# GD32W515 register map
File version: 1.0
CPU: CM33 r0p4, little endian, MPU, FPU, 4 interrupt priority bits
Registers are 32-bit, read-write, reset 0x0 unless marked. A register's access mark holds for its fields unless they carry their own. Offsets are from the block's base; [hi:lo] are bit positions; {n}, {i} and the like mark numbered series; 'fields as' and 'values as' point back to an identical list.

## PKCAU — Public Key Cryptographic Acceleration Unit
Base 0x4C061000
Same registers: SEC_PKCAU 0x5C061000
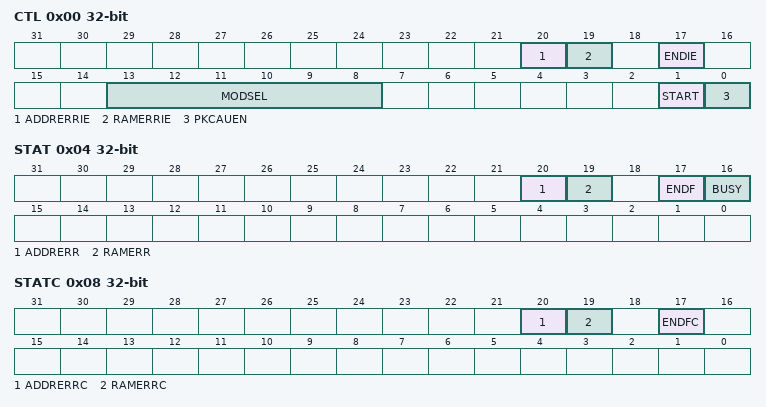
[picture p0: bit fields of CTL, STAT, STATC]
0x00 CTL — Control register
  [20] ADDRERRIE — Address error interrupt enable
  [19] RAMERRIE — RAM error interrupt enable
  [17] ENDIE — End of operation interrupt enable
  [13:8] MODSEL — PKCAU operation mode selection
  [1] START — PKCAU starts operation
  [0] PKCAUEN — PKCAU enable
0x04 STAT ro — Status register
  [20] ADDRERR — Address error
  [19] RAMERR — PKCAU RAM error
  [17] ENDF — End of PKCAU operation
  [16] BUSY — Busy flag
0x08 STATC wo — Status clear register
  [20] ADDRERRC — Address error flag clear
  [19] RAMERRC — PKCAU RAM error flag clear
  [17] ENDFC — End of PKCAU operation flag clear

## PMU — Power management unit
Base 0x40007000
Same registers: SEC_PMU 0x50007000
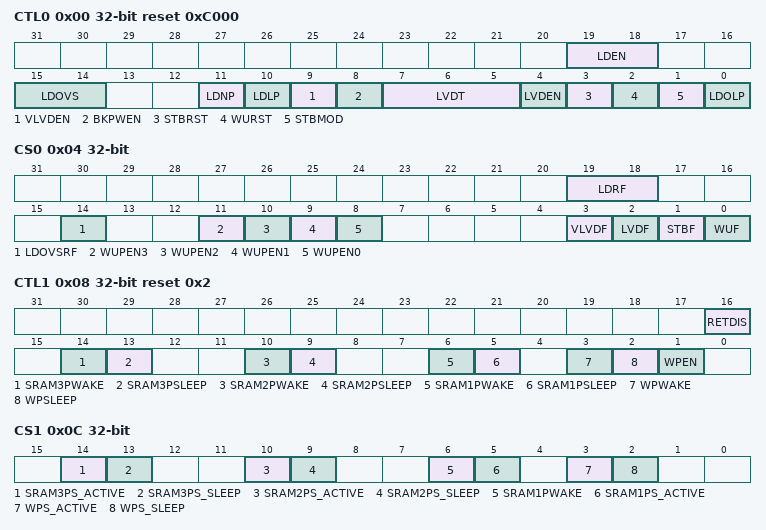
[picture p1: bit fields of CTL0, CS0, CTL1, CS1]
0x00 CTL0 reset 0xC000 — power control register 0
  [19:18] LDEN — Low-driver mode enable in Deep-sleep mode
  [15:14] LDOVS — LDO output voltage select
  [11] LDNP — Low-driver mode when use normal power LDO
  [10] LDLP — Low-driver mode when use low power LDO
  [9] VLVDEN — VDDA low voltage detect enable
  [8] BKPWEN — Backup Domain Write Enable
  [7:5] LVDT — Low Voltage Detector Threshold
  [4] LVDEN — Low Voltage Detector Enable
  [3] STBRST — Standby Flag Reset
  [2] WURST — Wakeup Flag Reset
  [1] STBMOD — Standby Mode
  [0] LDOLP — LDO Low Power Mode
0x04 CS0 access per field — power control/status register 0
  [19:18] LDRF rw — Low-driver mode ready flag
  [14] LDOVSRF ro — LDO voltage select ready flag
  [11] WUPEN3 rw — WKUP Pin3(PA12) Enable
  [10] WUPEN2 rw — WKUP Pin2(PB2) Enable
  [9] WUPEN1 rw — WKUP Pin1(PA15) Enable
  [8] WUPEN0 rw — WKUP Pin0(PA2) Enable
  [3] VLVDF ro — VDDA Low Voltage Detector Status Flag
  [2] LVDF ro — Low Voltage Detector Status Flag
  [1] STBF ro — Standby flag
  [0] WUF ro — Wakeup flag
0x08 CTL1 reset 0x2 — Control register 1
  [16] RETDIS — No retention register when WIFI por-off
  [14] SRAM3PWAKE — SRAM3 wakeup by software
  [13] SRAM3PSLEEP — SRAM3 go to sleep by software
  [10] SRAM2PWAKE — SRAM2 wakeup by software
  [9] SRAM2PSLEEP — SRAM2 go to sleep by software
  [6] SRAM1PWAKE — SRAM1 wakeup by software
  [5] SRAM1PSLEEP — SRAM1 go to sleep by software
  [3] WPWAKE — WIFI wakeup
  [2] WPSLEEP — WIFI go to sleep by software only when WPEN bit is 1
  [1] WPEN — WIFI power enable
0x0C CS1 ro — Control and status register 1
  [14] SRAM3PS_ACTIVE — SRAM3 is in active state
  [13] SRAM3PS_SLEEP — SRAM3 is in sleep state
  [10] SRAM2PS_ACTIVE — SRAM2 is in active state
  [9] SRAM2PS_SLEEP — SRAM2 is in sleep state
  [6] SRAM1PWAKE — SRAM1 wakeup by software
  [5] SRAM1PS_ACTIVE — SRAM1 is in active state
  [3] WPS_ACTIVE — WIFI is in active state
  [2] WPS_SLEEP — WIFI is in sleep state
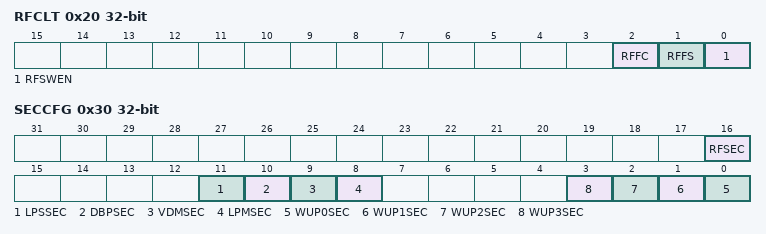
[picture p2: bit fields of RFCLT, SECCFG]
0x20 RFCLT — RF Control register
  [2] RFFC
  [1] RFFS
  [0] RFSWEN — RF sequence configured
0x30 SECCFG — Secure configuration register
  [16] RFSEC — RF security
  [11] LPSSEC — WIFI_sleep and SRAM_sleep mode security
  [10] DBPSEC — Backup Domain write access security
  [9] VDMSEC — Voltage detection and monitoring security
  [8] LPMSEC — Low-power mode security
  [n] WUP{n}SEC (n=0..3) — WKUP pin {n} security
0x34 PRICFG — Privilege configuration register
  [0] PRIV — PMU privileged access

## QSPI — Quad-SPI interface
Base 0x40025800
Same registers: SEC_QSPI 0x50025800
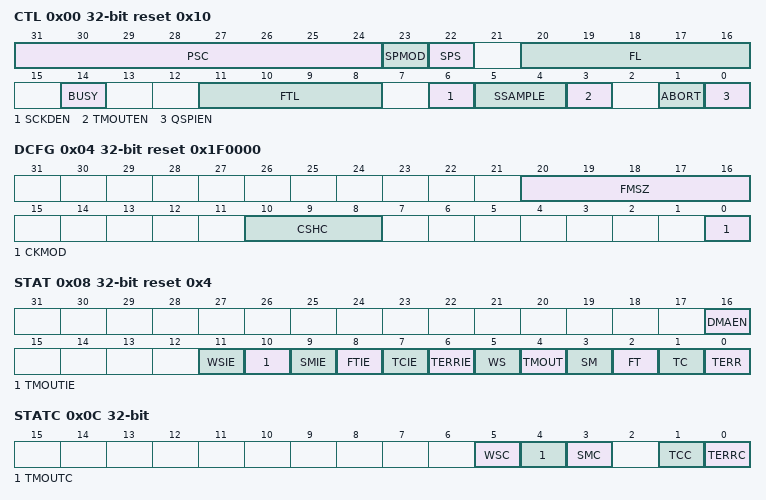
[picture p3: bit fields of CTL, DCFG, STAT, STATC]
0x00 CTL access per field reset 0x10 — Control register
  [31:24] PSC rw — This field defines the scaler factor for generating SCK based on the AHB clock
  [23] SPMOD rw — Status Polling match mode
  [22] SPS rw — Status polling mode stop
  [20:16] FL ro — FIFO level
  [14] BUSY ro
  [11:8] FTL rw — FIFO threshold level
  [6] SCKDEN rw — SCK delay enable when read data from flash, it is only useful when sample shift is 1
  [5:4] SSAMPLE rw — Sample shift
  [3] TMOUTEN rw — Timeout counter enable
  [1] ABORT wo — Abort request
  [0] QSPIEN rw — Enable
0x04 DCFG reset 0x1F0000 — Device configuration register
  [20:16] FMSZ — Flash memory size
  [10:8] CSHC — Chip select high cycle
  [0] CKMOD — This bit indicates the SCK level when QSPI is free.
0x08 STAT access per field reset 0x4 — Status register
  [16] DMAEN rw — DMA enable
  [11] WSIE rw — Wrong start sequence interrupt enable
  [10] TMOUTIE rw — Timeout interrupt enable
  [9] SMIE rw — Status match interrupt enable
  [8] FTIE rw — FIFO threshold interrupt enable
  [7] TCIE rw — Transfer complete interrupt enable
  [6] TERRIE rw — Transfer error interrupt enable
  [5] WS ro — Wrong start sequence flag
  [4] TMOUT ro — Timeout flag
  [3] SM ro — Status match flag
  [2] FT ro — FIFO threshold flag
  [1] TC ro — Transfer complete flag
  [0] TERR ro — Transfer error flag
0x0C STATC wo — Status clear register
  [5] WSC — Clear wrong start sequence flag
  [4] TMOUTC — Clear timeout flag
  [3] SMC — Clear read polling mode match flag
  [1] TCC — Clear transfer complete flag
  [0] TERRC — Clear transfer error flag
0x10 DTLEN — Data length register
  [31:0] DTLEN — Data length
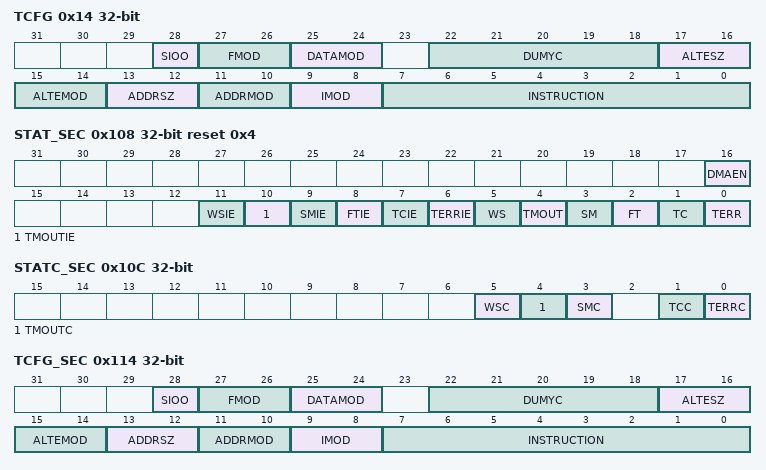
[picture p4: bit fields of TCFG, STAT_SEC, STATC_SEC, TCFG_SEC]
0x14 TCFG — Transfer configuration register
  [28] SIOO — Send instruction only once mode
  [27:26] FMOD — Functional mode
  [25:24] DATAMOD — Data mode
  [22:18] DUMYC — Number of dummy cycles
  [17:16] ALTESZ — Alternate bytes size
  [15:14] ALTEMOD — Alternate bytes mode
  [13:12] ADDRSZ — Address size
  [11:10] ADDRMOD — Address mode
  [9:8] IMOD — Instruction mode
  [7:0] INSTRUCTION
0x18 ADDR — Address register
  [31:0] ADDR — Address to be send to the external Flash memory
0x1C ALTE — Alternate bytes register
  [31:0] ALTE — Alternate Bytes
0x20 DATA
  [31:0] DATA — Data that will be interacting with flash memory.
0x24 STATMK — Status mask register
  [31:0] MASK — Status mask in read polling mode
0x28 STATMATCH — Status match register
  [31:0] MATCH — Status match in read polling mode
0x2C INTERVAL
  [15:0] INTERVAL — Interval cycle
0x30 TMOUT — Timeout register
  [15:0] TMOUTCYC — Timeout cycle
0x34 FLUSH wo — FIFO flush register
  [0] FLUSH — Used to flush all qspi interal fifo.
0x38 WTCNT reset 0x7A120 — Wait cnt for normal wire mode register
  [31:0] WTCNT — Wait cnt when an normal write operation is completed or aborted.
0x108 STAT_SEC access per field reset 0x4 — Secure Status register
  fields as STAT
0x10C STATC_SEC wo — Secure Status clear register
  [5] WSC — Clear wrong start sequence flag
  [4] TMOUTC — Clear timeout flag
  [3] SMC — Clear status match flag
  [1] TCC — Clear transfer complete flag
  [0] TERRC — Clear transfer error flag
0x110 DTLEN_SEC — Secure Data length register
  [31:0] DTLEN — Data length
0x114 TCFG_SEC — Secure Transfer configuration register
  fields as TCFG
0x118 ADDR_SEC — Secure Address register
  [31:0] ADDR — Address
0x11C ALTE_SEC — Secure Alternate bytes register
  [31:0] ALTE — Alternate Bytes
0x120 DATA_SEC — Secure Data register
  [31:0] DATA
